# MB9BF61xS register map
File version: 1.8
CPU: 
Registers are 32-bit, read-write, reset 0x0 unless marked. A register's access mark holds for its fields unless they carry their own. Offsets are from the block's base; [hi:lo] are bit positions; {n}, {i} and the like mark numbered series.

## EXBUS — External Bus Interface
Base 0x4003F000
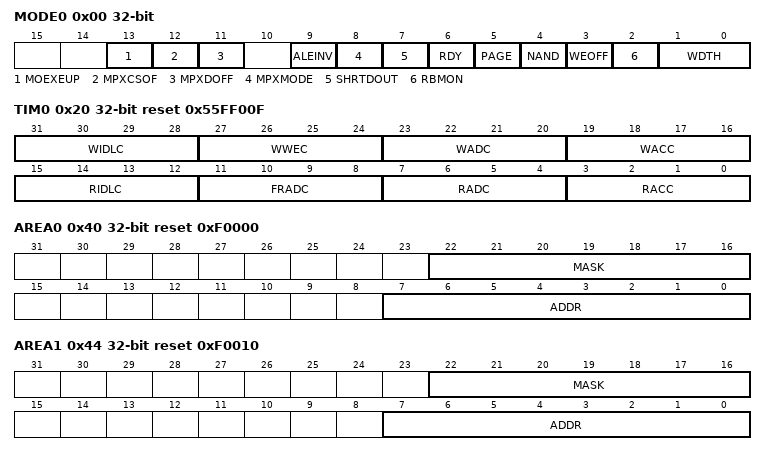
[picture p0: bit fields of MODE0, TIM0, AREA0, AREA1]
0x00 MODE0 — Mode Register 0
  [13] MOEXEUP — select how to set the MOEX width
  [12] MPXCSOF — select a CS assertion from the start of accessing to the end of address output
  [11] MPXDOFF — select whether or not the address is output to the data lines in multiplex mode
  [9] ALEINV — set up the polarity of the ALE signal
  [8] MPXMODE — select operation bus mode
  [7] SHRTDOUT — select to which idle cycle the write data output is extended
  [6] RDY — control the external RDY function
  [5] PAGE — NOR Flash memory page access mode
  [4] NAND — NAND Flash memory mode
  [3] WEOFF — disable the write enable signal (MWEX) operation
  [2] RBMON — Read Byte Mask ON
  [1:0] WDTH — specify Data Width
{0x0+4i} MODE{i} reset not defined (i=1..7) — Mode Register {i}
0x20 TIM0 reset 0x55FF00F — Timing Register 0
  [31:28] WIDLC — Write Idle Cycle
  [27:24] WWEC — Write Enable Cycle
  [23:20] WADC — Write Address Setup cycle
  [19:16] WACC — Write Access Cycle
  [15:12] RIDLC — Read Idle Cycle
  [11:8] FRADC — First Read Address Cycle
  [7:4] RADC — Read Address Setup cycle
  [3:0] RACC — Read Access Cycle
{0x20+4i} TIM{i} reset not defined (i=1..7) — Timing Register {i}
0x40 AREA0 reset 0xF0000 — Area Register 0
  [22:16] MASK — address mask
  [7:0] ADDR — Address
0x44 AREA1 reset 0xF0010 — Area Register 1
  [22:16] MASK — address mask
  [7:0] ADDR — Address
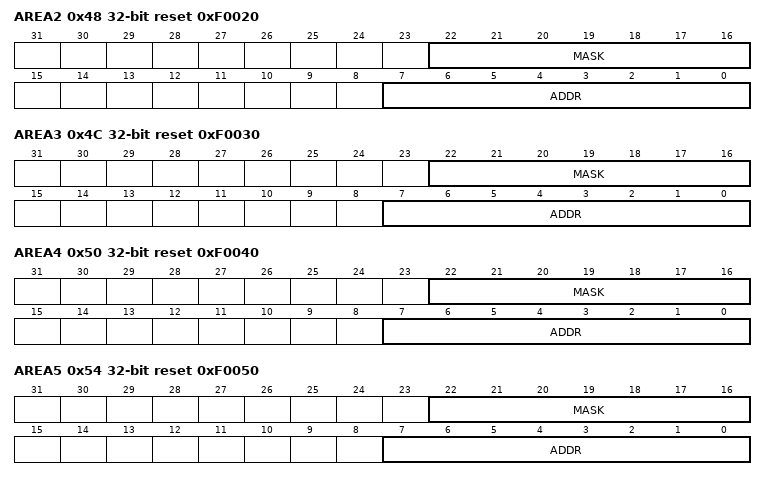
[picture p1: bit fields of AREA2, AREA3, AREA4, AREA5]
0x48 AREA2 reset 0xF0020 — Area Register 2
  [22:16] MASK — address mask
  [7:0] ADDR — Address
0x4C AREA3 reset 0xF0030 — Area Register 3
  [22:16] MASK — address mask
  [7:0] ADDR — Address
0x50 AREA4 reset 0xF0040 — Area Register 4
  [22:16] MASK — address mask
  [7:0] ADDR — Address
0x54 AREA5 reset 0xF0050 — Area Register 5
  [22:16] MASK — address mask
  [7:0] ADDR — Address
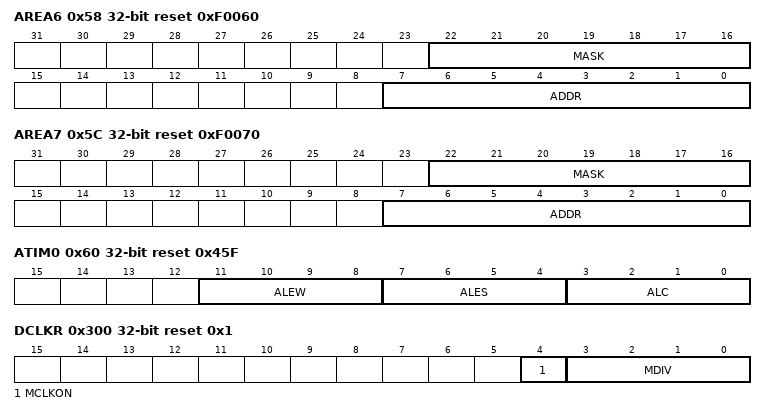
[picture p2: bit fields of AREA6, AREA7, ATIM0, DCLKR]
0x58 AREA6 reset 0xF0060 — Area Register 6
  [22:16] MASK — address mask
  [7:0] ADDR — Address
0x5C AREA7 reset 0xF0070 — Area Register 7
  [22:16] MASK — address mask
  [7:0] ADDR — Address
0x60 ATIM0 reset 0x45F — ALE Timing Register 0
  [11:8] ALEW — Address Latch Enable Width
  [7:4] ALES — Address Latch Enable Setup cycle
  [3:0] ALC — Address Latch Cycle
{0x60+4i} ATIM{i} reset not defined (i=1..7) — ALE Timing Register {i}
0x300 DCLKR reset 0x1 (reset mask 0xF) — Division Clock Register
  [4] MCLKON
  [3:0] MDIV — MCLK Division Ratio Setup

## USBETHERCLK — USB/Ethernet Clock
Base 0x40036000
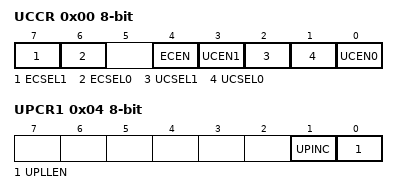
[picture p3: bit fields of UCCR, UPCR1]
0x00 UCCR 8-bit (reset mask 0x7F) — USB/Ethernet-PLL Clock Control Register
  [7] ECSEL1 — Ethernet clock selection bit 1
  [6] ECSEL0 — Ethernet clock selection bit 0
  [4] ECEN — Ethernet clock output enable bit
  [3] UCEN1 — USB1 clock output enable bit
  [2] UCSEL1 — USB1 clock selection bit
  [1] UCSEL0 — USB0 clock selection bit
  [0] UCEN0 — USB0 clock output enable bit
0x04 UPCR1 8-bit — USB/Ethernet-PLL Control Register 1
  [1] UPINC — USB/Ethernet-PLL input clock selection bit
  [0] UPLLEN — USB/Ethernet-PLL oscillation enable bit
0x08 UPCR2 8-bit — USB/Ethernet-PLL Control Register 2
  [2:0] UPOWT — USB/Ethernet-PLL oscillation stabilization wait time setting bit
0x0C UPCR3 8-bit — USB/Ethernet-PLL Control Register 3
  [4:0] UPLLK — Frequency division ratio (K) setting bit of the USB/Ethernet-PLL clock
0x10 UPCR4 8-bit reset 0x3B — USB/Ethernet-PLL Control Register 4
  [6:0] UPLLN — Frequency division ratio (N) setting bit of the USB/Ethernet-PLL clock
0x14 UP_STR 8-bit ro — USB/Ethernet-PLL Status Register
  [0] UPRDY — USB/Ethernet-PLL oscillation stabilization bit
0x18 UPINT_ENR 8-bit — USB/Ethernet-PLL Interrupt Source Enable Register
  [0] UPCSE — USB/Ethernet-PLL oscillation stabilization wait complete interrupt enable bit
0x1C UPINT_CLR 8-bit wo — USB/Ethernet-PLL Interrupt Source Clear Register
  [0] UPCSC — USB/Ethernet-PLL oscillation stabilization interrupt source clear bit
0x20 UPINT_STR 8-bit ro — USB/Ethernet-PLL Interrupt Source Status Register
  [0] UPCSI — USB/Ethernet-PLL interrupt source status bit
0x24 UPCR5 8-bit reset 0x4 — USB/Ethernet-PLL Control Register 5
  [3:0] UPLLM — Frequency division ratio (M) setting bit of the USB/Ethernet-PLL clock
0x28 UPCR6 8-bit reset 0x2 — USB/Ethernet-PLL Setting Register 6
  [3:0] UBSR — CLKPLL division ratio setting bit
0x2C UPCR7 8-bit — USB/Ethernet-PLL Setting Register 7
  [0] EPLLEN — USB/Ethernet-PLL control bit in Timer mode
0x30 USBEN0 8-bit — USB0 Enable Register
  [0] USBEN0 — USB0 enable bit
0x34 USBEN1 8-bit — USB1 Enable Register
  [0] USBEN1 — USB1 enable bit

## DMAC — DMAC Registers
Base 0x40060000
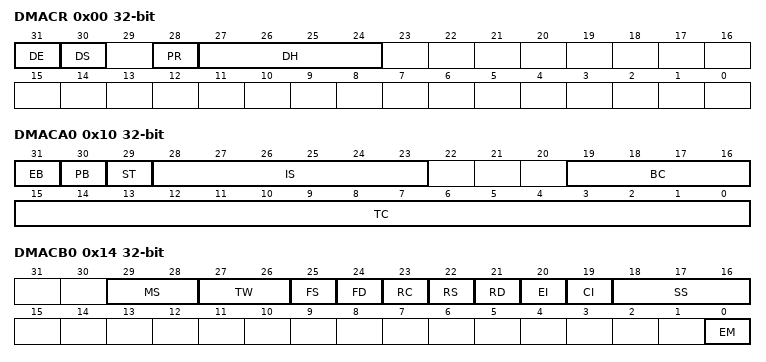
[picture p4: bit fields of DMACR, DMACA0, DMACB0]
0x00 DMACR — Entire DMAC Configuration Register
  [31] DE — DMA Enable (all-channel operation enable bit)
  [30] DS — DMA Stop
  [28] PR — Priority Rotation
  [27:24] DH — DMA Halt (All-channel pause bit)
0x10 DMACA0 — Configuration A Register
  [31] EB — Enable bit (individual-channel operation enable bit)
  [30] PB — Pause bit (individual-channel pause bit)
  [29] ST — Software Trigger
  [28:23] IS — Input Select
  [19:16] BC — Block Count
  [15:0] TC — Transfer Count
0x14 DMACB0 — Configuration B Register
  [29:28] MS — Mode Select
  [27:26] TW — Transfer Width
  [25] FS — Fixed Source
  [24] FD — Fixed Destination
  [23] RC — Reload Count (BC/TC reload)
  [22] RS — Reload Source
  [21] RD — Reload Destination
  [20] EI — Error Interrupt (unsuccessful transfer completion interrupt enable)
  [19] CI — Completion Interrupt (successful transfer completion interrupt enable)
  [18:16] SS — Stop Status (stop status notification)
  [0] EM — Enable bit Mask (EB bit clear mask)
0x18 DMACSA0 — Transfer Source Address Register
0x1C DMACDA0 — Transfer Destination Address Register
{0x10+0x10*i} DMACA{i} reset not defined (i=1..7) — Configuration A Register {i}
{0x14+0x10*i} DMACB{i} reset not defined (i=1..7) — Configuration B Register {i}
{0x18+0x10*i} DMACSA{i} reset not defined (i=1..7) — Transfer Source Address Register {i}
{0x1C+0x10*i} DMACDA{i} reset not defined (i=1..7) — Transfer Destination Address Register {i}

## ETHERNET_CONTROL — Ethernet system control
Base 0x40066000
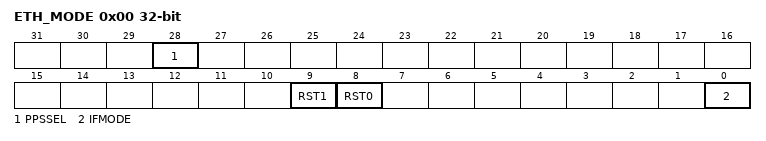
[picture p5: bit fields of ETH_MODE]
0x00 ETH_MODE — Mode Select Register
  [28] PPSSEL — Select either of the system time counter pulse outputs of the Ethernet-MAC PTP function to output to E_PPS0_PPS1 pin
  [9] RST1 — reset signal against Ethernet-MAC (ch.1)
  [8] RST0 — reset signal against Ethernet-MAC (ch.0)
  [0] IFMODE — Mode selector
0x08 ETH_CLKG — Clock Gating Register
  [1:0] MACEN — Select the system clock supply to Ethernet-MAC
